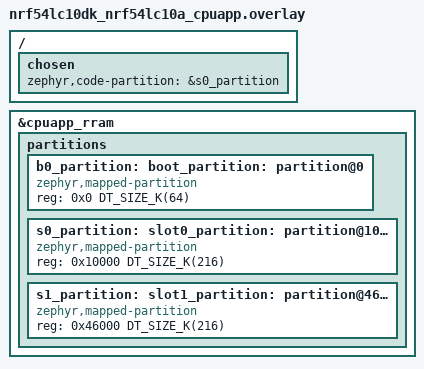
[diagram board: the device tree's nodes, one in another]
/*
 * Copyright (c) 2026 Nordic Semiconductor ASA
 *
 * SPDX-License-Identifier: LicenseRef-Nordic-5-Clause
 */

&cpuapp_rram {
	/delete-node/ partitions;

	partitions {
		ranges;
		#address-cells = <1>;
		#size-cells = <1>;

		b0_partition: boot_partition: partition@0 {
			compatible = "zephyr,mapped-partition";
			reg = <0x0 DT_SIZE_K(64)>;
		};

		s0_partition: slot0_partition: partition@10000 {
			compatible = "zephyr,mapped-partition";
			reg = <0x10000 DT_SIZE_K(216)>;
		};

		s1_partition: slot1_partition: partition@46000 {
			compatible = "zephyr,mapped-partition";
			reg = <0x46000 DT_SIZE_K(216)>;
		};
	};
};

/ {
	chosen {
		zephyr,code-partition = &s0_partition;
	};
};
